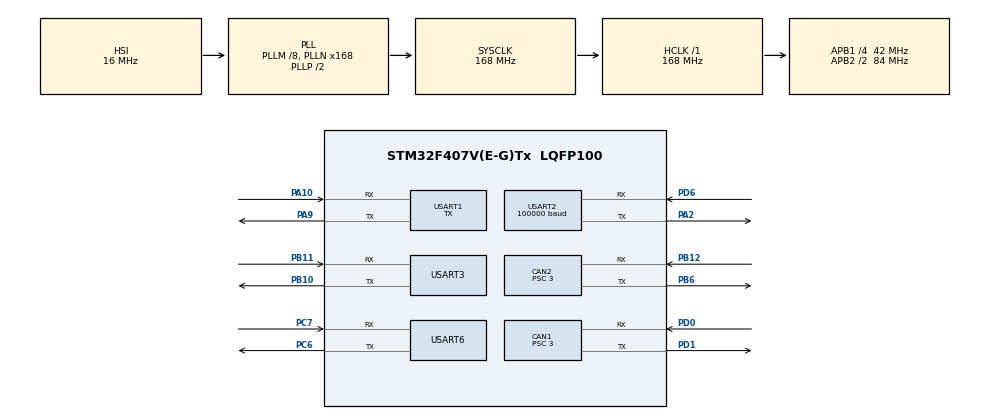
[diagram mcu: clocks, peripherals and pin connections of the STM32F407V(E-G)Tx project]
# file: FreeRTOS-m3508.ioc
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CAN1.BS1=CAN_BS1_9TQ
CAN1.BS2=CAN_BS2_4TQ
CAN1.CalculateBaudRate=1000000
CAN1.CalculateTimeBit=1000
CAN1.CalculateTimeQuantum=71.42857142857143
CAN1.Prescaler=3
CAN2.BS1=CAN_BS1_9TQ
CAN2.BS2=CAN_BS2_4TQ
CAN2.CalculateBaudRate=1000000
CAN2.CalculateTimeBit=1000
CAN2.CalculateTimeQuantum=71.42857142857143
CAN2.Prescaler=3
Dma.Request0=USART2_RX
Dma.Request1=USART3_RX
Dma.Request2=USART6_RX
Dma.USART2_RX.0.Direction=DMA_PERIPH_TO_MEMORY
Dma.USART2_RX.0.FIFOMode=DMA_FIFOMODE_DISABLE
Dma.USART2_RX.0.Instance=DMA1_Stream5
Dma.USART2_RX.0.MemDataAlignment=DMA_MDATAALIGN_BYTE
Dma.USART2_RX.0.MemInc=DMA_MINC_ENABLE
Dma.USART2_RX.0.Mode=DMA_CIRCULAR
Dma.USART2_RX.0.PeriphDataAlignment=DMA_PDATAALIGN_BYTE
Dma.USART2_RX.0.PeriphInc=DMA_PINC_DISABLE
Dma.USART2_RX.0.Priority=DMA_PRIORITY_VERY_HIGH
Dma.USART3_RX.1.Direction=DMA_PERIPH_TO_MEMORY
Dma.USART3_RX.1.FIFOMode=DMA_FIFOMODE_DISABLE
Dma.USART3_RX.1.Instance=DMA1_Stream1
Dma.USART3_RX.1.MemDataAlignment=DMA_MDATAALIGN_BYTE
Dma.USART3_RX.1.MemInc=DMA_MINC_ENABLE
Dma.USART3_RX.1.Mode=DMA_NORMAL
Dma.USART3_RX.1.PeriphDataAlignment=DMA_PDATAALIGN_BYTE
Dma.USART3_RX.1.PeriphInc=DMA_PINC_DISABLE
Dma.USART3_RX.1.Priority=DMA_PRIORITY_LOW
Dma.USART6_RX.2.Direction=DMA_PERIPH_TO_MEMORY
Dma.USART6_RX.2.FIFOMode=DMA_FIFOMODE_DISABLE
Dma.USART6_RX.2.Instance=DMA2_Stream1
Dma.USART6_RX.2.MemDataAlignment=DMA_MDATAALIGN_BYTE
Dma.USART6_RX.2.MemInc=DMA_MINC_ENABLE
Dma.USART6_RX.2.Mode=DMA_NORMAL
Dma.USART6_RX.2.PeriphDataAlignment=DMA_PDATAALIGN_BYTE
Dma.USART6_RX.2.PeriphInc=DMA_PINC_DISABLE
Dma.USART6_RX.2.Priority=DMA_PRIORITY_LOW
FREERTOS.Tasks01=chassis,24,128,chassis_task,As weak,NULL,Dynamic,NULL,NULL;myTask02,24,128,StartTask02,Default,NULL,Dynamic,NULL,NULL;DetectTask,8,128,Detect_Task,As weak,NULL,Dynamic,NULL,NULL
Mcu.Family=STM32F4
Mcu.Name=STM32F407V(E-G)Tx
Mcu.Package=LQFP100
NVIC.CAN1_RX0_IRQn=true\:5\:0\:false\:true\:true\:2\:true\:true\:true\:true
NVIC.CAN2_RX0_IRQn=true\:5\:0\:true\:false\:true\:true\:true\:true\:true
NVIC.DMA1_Stream1_IRQn=true\:5\:0\:true\:false\:true\:true\:false\:true\:true
NVIC.DMA1_Stream5_IRQn=true\:5\:0\:false\:true\:true\:3\:true\:false\:true\:true
NVIC.DMA2_Stream1_IRQn=true\:5\:0\:false\:false\:true\:true\:false\:true\:true
NVIC.PriorityGroup=NVIC_PRIORITYGROUP_4
NVIC.TIM8_TRG_COM_TIM14_IRQn=true\:0\:0\:false\:false\:true\:false\:false\:true\:true
NVIC.TimeBase=TIM8_TRG_COM_TIM14_IRQn
NVIC.TimeBaseIP=TIM14
NVIC.USART2_IRQn=true\:5\:0\:false\:true\:true\:1\:true\:true\:true\:true
NVIC.USART3_IRQn=true\:0\:0\:false\:false\:true\:false\:true\:true\:true
PA10.Mode=Asynchronous
PA10.Signal=USART1_RX
PA13.Mode=Serial_Wire
PA13.Signal=SYS_JTMS-SWDIO
PA14.Mode=Serial_Wire
PA14.Signal=SYS_JTCK-SWCLK
PA2.Mode=Asynchronous
PA2.Signal=USART2_TX
PA9.Mode=Asynchronous
PA9.Signal=USART1_TX
PB10.Mode=Asynchronous
PB10.Signal=USART3_TX
PB11.Mode=Asynchronous
PB11.Signal=USART3_RX
PB12.Mode=CAN_Activate
PB12.Signal=CAN2_RX
PB6.Mode=CAN_Activate
PB6.Signal=CAN2_TX
PC6.Mode=Asynchronous
PC6.Signal=USART6_TX
PC7.Mode=Asynchronous
PC7.Signal=USART6_RX
PD0.Mode=CAN_Activate
PD0.Signal=CAN1_RX
PD1.Mode=CAN_Activate
PD1.Signal=CAN1_TX
PD6.Mode=Asynchronous
PD6.Signal=USART2_RX
PH0-OSC_IN.Mode=HSE-External-Oscillator
PH0-OSC_IN.Signal=RCC_OSC_IN
PH1-OSC_OUT.Mode=HSE-External-Oscillator
PH1-OSC_OUT.Signal=RCC_OSC_OUT
ProjectManager.HeapSize=0x200
ProjectManager.StackSize=0x400
ProjectManager.TargetToolchain=MDK-ARM V5.27
RCC.48MHZClocksFreq_Value=84000000
RCC.AHBFreq_Value=168000000
RCC.APB1CLKDivider=RCC_HCLK_DIV4
RCC.APB1Freq_Value=42000000
RCC.APB1TimFreq_Value=84000000
RCC.APB2CLKDivider=RCC_HCLK_DIV2
RCC.APB2Freq_Value=84000000
RCC.APB2TimFreq_Value=168000000
RCC.CortexFreq_Value=168000000
RCC.HCLKFreq_Value=168000000
RCC.HSE_VALUE=8000000
RCC.HSI_VALUE=16000000
RCC.LSE_VALUE=32768
RCC.PLLM=8
RCC.PLLN=168
RCC.SYSCLKFreq_VALUE=168000000
RCC.SYSCLKSource=RCC_SYSCLKSOURCE_PLLCLK
RCC.VCOOutputFreq_Value=336000000
USART1.Mode=MODE_TX
USART1.VirtualMode=VM_ASYNC
USART2.BaudRate=100000
USART2.Parity=PARITY_EVEN
USART2.VirtualMode=VM_ASYNC
USART3.VirtualMode=VM_ASYNC
USART6.VirtualMode=VM_ASYNC
VP_FREERTOS_VS_CMSIS_V2.Mode=CMSIS_V2
VP_SYS_VS_tim14.Mode=TIM14
board=custom

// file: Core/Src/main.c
/* USER CODE BEGIN Header */
/**
  ******************************************************************************
  * @file           : main.c
  * @brief          : Main program body
  ******************************************************************************
  * @attention
  *
  * <h2><center>&copy; Copyright (c) 2022 STMicroelectronics.
  * All rights reserved.</center></h2>
  *
  * This software component is licensed by ST under Ultimate Liberty license
  * SLA0044, the "License"; You may not use this file except in compliance with
  * the License. You may obtain a copy of the License at:
  *                             www.st.com/SLA0044
  *
  ******************************************************************************
  */
/* USER CODE END Header */
#include "main.h"
#include "cmsis_os.h"
#include "can.h"
#include "dma.h"
#include "usart.h"
#include "gpio.h"

/* USER CODE BEGIN Includes */
#include "bsp_dma.h"
#include "bsp_can.h"
#include "pid.h"
/* USER CODE END Includes */

void SystemClock_Config(void);
void MX_FREERTOS_Init(void);
static void MX_NVIC_Init(void);

int main(void)
{

  /* MCU Configuration--------------------------------------------------------*/

  /* Reset of all peripherals, Initializes the Flash interface and the Systick. */
  HAL_Init();

  /* Configure the system clock */
  SystemClock_Config();

  /* Initialize all configured peripherals */
  MX_GPIO_Init();
  MX_DMA_Init();
  MX_CAN1_Init();
  MX_USART2_UART_Init();
  MX_USART1_UART_Init();
  MX_USART6_UART_Init();
  MX_CAN2_Init();
  MX_USART3_UART_Init();

  /* Initialize interrupts */
  MX_NVIC_Init();
  /* USER CODE BEGIN 2 */
   Can_init(); //can的初始化
	 Can2_init();
	 remote_control_init();
  /* USER CODE END 2 */

  /* Init scheduler */
  osKernelInitialize();  /* Call init function for freertos objects (in freertos.c) */
  MX_FREERTOS_Init();

  /* Start scheduler */
  osKernelStart();

  /* We should never get here as control is now taken by the scheduler */
  /* Infinite loop */
  while (1)
  {

  }
}

void SystemClock_Config(void)
{
  RCC_OscInitTypeDef RCC_OscInitStruct = {0};
  RCC_ClkInitTypeDef RCC_ClkInitStruct = {0};

  /** Configure the main internal regulator output voltage
  */
  __HAL_RCC_PWR_CLK_ENABLE();
  __HAL_PWR_VOLTAGESCALING_CONFIG(PWR_REGULATOR_VOLTAGE_SCALE1);

  /** Initializes the RCC Oscillators according to the specified parameters
  * in the RCC_OscInitTypeDef structure.
  */
  RCC_OscInitStruct.OscillatorType = RCC_OSCILLATORTYPE_HSI;
  RCC_OscInitStruct.HSIState = RCC_HSI_ON;
  RCC_OscInitStruct.HSICalibrationValue = RCC_HSICALIBRATION_DEFAULT;
  RCC_OscInitStruct.PLL.PLLState = RCC_PLL_ON;
  RCC_OscInitStruct.PLL.PLLSource = RCC_PLLSOURCE_HSI;
  RCC_OscInitStruct.PLL.PLLM = 8;
  RCC_OscInitStruct.PLL.PLLN = 168;
  RCC_OscInitStruct.PLL.PLLP = RCC_PLLP_DIV2;
  RCC_OscInitStruct.PLL.PLLQ = 4;
  if (HAL_RCC_OscConfig(&RCC_OscInitStruct) != HAL_OK)
  {
    Error_Handler();
  }

  /** Initializes the CPU, AHB and APB buses clocks
  */
  RCC_ClkInitStruct.ClockType = RCC_CLOCKTYPE_HCLK|RCC_CLOCKTYPE_SYSCLK
                              |RCC_CLOCKTYPE_PCLK1|RCC_CLOCKTYPE_PCLK2;
  RCC_ClkInitStruct.SYSCLKSource = RCC_SYSCLKSOURCE_PLLCLK;
  RCC_ClkInitStruct.AHBCLKDivider = RCC_SYSCLK_DIV1;
  RCC_ClkInitStruct.APB1CLKDivider = RCC_HCLK_DIV4;
  RCC_ClkInitStruct.APB2CLKDivider = RCC_HCLK_DIV2;

  if (HAL_RCC_ClockConfig(&RCC_ClkInitStruct, FLASH_LATENCY_5) != HAL_OK)
  {
    Error_Handler();
  }
}

/**
  * @brief NVIC Configuration.
  * @retval None
  */
static void MX_NVIC_Init(void)
{
  /* USART2_IRQn interrupt configuration */
  HAL_NVIC_SetPriority(USART2_IRQn, 5, 0);
  HAL_NVIC_EnableIRQ(USART2_IRQn);
  /* CAN1_RX0_IRQn interrupt configuration */
  HAL_NVIC_SetPriority(CAN1_RX0_IRQn, 5, 0);
  HAL_NVIC_EnableIRQ(CAN1_RX0_IRQn);
  /* DMA1_Stream5_IRQn interrupt configuration */
  HAL_NVIC_SetPriority(DMA1_Stream5_IRQn, 5, 0);
  HAL_NVIC_EnableIRQ(DMA1_Stream5_IRQn);
}

void HAL_TIM_PeriodElapsedCallback(TIM_HandleTypeDef *htim)
{
  if (htim->Instance == TIM14) {
    HAL_IncTick();
  }
}

void Error_Handler(void)
{
  __disable_irq();
  while (1)
  {
  }
}

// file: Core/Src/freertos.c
/* USER CODE BEGIN Header */
/**
  ******************************************************************************
  * File Name          : freertos.c
  * Description        : Code for freertos applications
  ******************************************************************************
  * @attention
  *
  * <h2><center>&copy; Copyright (c) 2022 STMicroelectronics.
  * All rights reserved.</center></h2>
  *
  * This software component is licensed by ST under Ultimate Liberty license
  * SLA0044, the "License"; You may not use this file except in compliance with
  * the License. You may obtain a copy of the License at:
  *                             www.st.com/SLA0044
  *
  ******************************************************************************
  */
/* USER CODE END Header */

#include "FreeRTOS.h"
#include "task.h"
#include "main.h"
#include "cmsis_os.h"

/* USER CODE BEGIN Includes */
#include "pid.h"

#include "Nground.h"
int i;
int16_t speed;
/* USER CODE END Includes */

/* Definitions for chassis */
osThreadId_t chassisHandle;
const osThreadAttr_t chassis_attributes = {
  .name = "chassis",
  .stack_size = 128 * 4,
  .priority = (osPriority_t) osPriorityNormal,
};
/* Definitions for myTask02 */
osThreadId_t myTask02Handle;
const osThreadAttr_t myTask02_attributes = {
  .name = "myTask02",
  .stack_size = 128 * 4,
  .priority = (osPriority_t) osPriorityNormal,
};
/* Definitions for DetectTask */
osThreadId_t DetectTaskHandle;
const osThreadAttr_t DetectTask_attributes = {
  .name = "DetectTask",
  .stack_size = 128 * 4,
  .priority = (osPriority_t) osPriorityLow,
};

void chassis_task(void *argument);
void StartTask02(void *argument);
void Detect_Task(void *argument);

void MX_FREERTOS_Init(void); /* (MISRA C 2004 rule 8.1) */

void MX_FREERTOS_Init(void) {

  /* Create the thread(s) */
  /* creation of chassis */
  chassisHandle = osThreadNew(chassis_task, NULL, &chassis_attributes);

  /* creation of myTask02 */
  myTask02Handle = osThreadNew(StartTask02, NULL, &myTask02_attributes);

  /* creation of DetectTask */
  DetectTaskHandle = osThreadNew(Detect_Task, NULL, &DetectTask_attributes);

}

__weak void chassis_task(void *argument)
{
  for(;;)
  {
    osDelay(1);
  }
}

void StartTask02(void *argument)
{
  /* USER CODE BEGIN StartTask02 */
  /* Infinite loop */
  for(;;)
  {
		NCLink_Send_Userdata(1,1,1,1,1,1);
    osDelay(10);
  }
  /* USER CODE END StartTask02 */
}

__weak void Detect_Task(void *argument)
{
  for(;;)
  {
    osDelay(1);
  }
}
